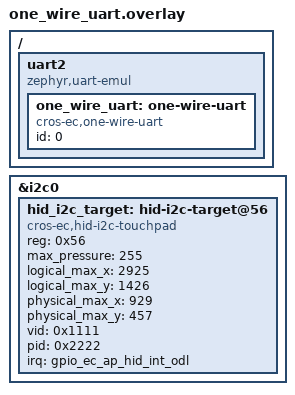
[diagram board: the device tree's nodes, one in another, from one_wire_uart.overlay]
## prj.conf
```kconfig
# Copyright 2023 The ChromiumOS Authors
# Use of this source code is governed by a BSD-style license that can be
# found in the LICENSE file.

CONFIG_ZTEST=y
CONFIG_ZTEST_NEW_API=y
CONFIG_PLATFORM_EC=y
CONFIG_CROS_EC=y

CONFIG_PLATFORM_EC_ONE_WIRE_UART_TABLET=y
CONFIG_PLATFORM_EC_ONE_WIRE_UART_KEYBOARD=y
```

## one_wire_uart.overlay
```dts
/* Copyright 2023 The ChromiumOS Authors
 * Use of this source code is governed by a BSD-style license that can be
 * found in the LICENSE file.
 */

#include <board-overlays/native_posix.dts>

/ {
	uart2 {
		compatible = "zephyr,uart-emul";
		status = "okay";

		one_wire_uart: one-wire-uart {
			compatible = "cros-ec,one-wire-uart";
			status = "okay";
			id = <0>;
		};
	};
};

&i2c0 {
	hid_i2c_target: hid-i2c-target@56 {
		compatible = "cros-ec,hid-i2c-touchpad";

		reg = <0x56>;
		max_pressure = <255>;
		logical_max_x = <2925>;
		logical_max_y = <1426>;
		physical_max_x = <929>;
		physical_max_y = <457>;

		vid = <0x1111>;
		pid = <0x2222>;

		irq = <&gpio_ec_ap_hid_int_odl>;
	};
};
```

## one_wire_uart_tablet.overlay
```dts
/* Copyright 2023 The ChromiumOS Authors
 * Use of this source code is governed by a BSD-style license that can be
 * found in the LICENSE file.
 */

&i2c0 {
	hid_i2c_target: hid-i2c-target@57 {
		compatible = "cros-ec,hid-i2c-touchpad";

		reg = <0x56>;
		max-pressure = <255>;
		logical-max-x = <2925>;
		logical-max-y = <1426>;
		physical-max-x = <929>;
		physical-max-y = <457>;

		vid = <0x1111>;
		pid = <0x2222>;

		irq-gpios = <&gpio1 16 GPIO_ACTIVE_LOW>;
	};
};
```

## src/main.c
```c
/* Copyright 2023 The ChromiumOS Authors
 * Use of this source code is governed by a BSD-style license that can be
 * found in the LICENSE file.
 */
#include "drivers/one_wire_uart.h"
#include "drivers/one_wire_uart_internal.h"
#include "test/drivers/test_state.h"
#include "test/drivers/utils.h"
#include "timer.h"

#include <stdint.h>
#include <stdlib.h>

#include <zephyr/device.h>
#include <zephyr/devicetree.h>
#include <zephyr/fff.h>
#include <zephyr/ztest_assert.h>
#include <zephyr/ztest_test.h>

const static struct device *dev = DEVICE_DT_GET(DT_NODELABEL(one_wire_uart));

FAKE_VOID_FUNC(on_message_received, uint8_t, const uint8_t *, int);

ZTEST(one_wire_uart_driver, test_checksum)
{
	struct one_wire_uart_message msg;

	memset(&msg, 0, sizeof(msg));
	msg.header.payload_len = 5;
	msg.payload[0] = 0xA1;
	msg.payload[1] = 0xA2;
	msg.payload[2] = 0xA3;
	msg.payload[3] = 0xA4;
	msg.payload[4] = 0xA5;

	/* 16bit words in the msg are [0x0500, 0x0000, 0xA100, 0xA3A2, 0xA5A4]
	 * sum = 0x1EF46 => carry back => 0xEF47
	 */
	zassert_equal(checksum(&msg), 0xEF47);
}

ZTEST(one_wire_uart_driver, test_send)
{
	struct one_wire_uart_data *data = dev->data;
	struct k_msgq *tx_queue = data->tx_queue;

	struct one_wire_uart_message msg;

	one_wire_uart_send(dev, 5, (uint8_t[]){ 6, 7, 8 }, 3);

	k_msgq_get(tx_queue, &msg, K_NO_WAIT);

	zassert_equal(msg.payload[0], 5);
	zassert_equal(msg.payload[1], 6);
	zassert_equal(msg.payload[2], 7);
	zassert_equal(msg.payload[3], 8);
}

ZTEST(one_wire_uart_driver, test_rx)
{
	struct one_wire_uart_data *data = dev->data;
	struct one_wire_uart_message msg;
	uint8_t junk[10] = {};

	memset(&msg, 0, sizeof(msg));

	/* push some junk data first */
	ring_buf_put(data->rx_ring_buf, junk, sizeof(junk));

	/* push 3 messages
	 * expect that on_message_received callback only triggered on the last
	 * message which sender == 1.
	 */
	msg.header.magic = 0xEC;
	msg.header.payload_len = 2;
	msg.payload[0] = 56;
	msg.header.sender = 0;
	msg.header.msg_id = 11;
	msg.header.checksum = 0;
	msg.header.checksum = checksum(&msg);
	ring_buf_put(data->rx_ring_buf, (uint8_t *)&msg,
		     sizeof(msg.header) + 2);

	msg.header.magic = 0xEC;
	msg.header.payload_len = 1;
	msg.payload[0] = 56;
	msg.header.sender = 0;
	msg.header.msg_id = 12;
	msg.header.checksum = 0;
	msg.header.checksum = checksum(&msg);
	ring_buf_put(data->rx_ring_buf, (uint8_t *)&msg,
		     sizeof(msg.header) + 1);

	msg.header.magic = 0xEC;
	msg.header.payload_len = 1;
	msg.payload[0] = 56;
	msg.header.sender = 1;
	msg.header.msg_id = 22;
	msg.header.checksum = 0;
	msg.header.checksum = checksum(&msg);
	ring_buf_put(data->rx_ring_buf, (uint8_t *)&msg,
		     sizeof(msg.header) + 1);

	/* push more junk */
	ring_buf_put(data->rx_ring_buf, junk, sizeof(junk));

	process_rx_fifo(dev);
	process_packet();

	zassert_equal(ring_buf_size_get(data->rx_ring_buf), 0);
	zassert_equal(on_message_received_fake.call_count, 1, "call count %d",
		      on_message_received_fake.call_count);
}

ZTEST(one_wire_uart_driver, test_rx_partial)
{
	struct one_wire_uart_data *data = dev->data;
	struct one_wire_uart_message msg;

	memset(&msg, 0, sizeof(msg));
	msg.header.magic = 0xEC;
	msg.header.payload_len = 10;
	msg.payload[0] = 56;
	msg.header.sender = 1;
	msg.header.msg_id = 11;
	msg.header.checksum = 0;
	msg.header.checksum = checksum(&msg);
	/* put 1 byte payload into ring_buf, discard other 9 bytes */
	ring_buf_put(data->rx_ring_buf, (uint8_t *)&msg,
		     sizeof(msg.header) + 1);

	one_wire_uart_set_callback(dev, on_message_received);

	process_rx_fifo(dev);
	process_packet();

	zassert_equal(on_message_received_fake.call_count, 0);
	zassert_not_equal(ring_buf_size_get(data->rx_ring_buf), 0);
}

ZTEST(one_wire_uart_driver, test_rx_bad_checksum)
{
	struct one_wire_uart_data *data = dev->data;
	struct one_wire_uart_message msg;

	memset(&msg, 0, sizeof(msg));
	msg.header.magic = 0xEC;
	msg.header.payload_len = 0;
	msg.header.sender = 1;
	msg.header.msg_id = 11;
	msg.header.checksum = 0;
	ring_buf_put(data->rx_ring_buf, (uint8_t *)&msg, sizeof(msg.header));

	one_wire_uart_set_callback(dev, on_message_received);

	process_rx_fifo(dev);
	process_packet();

	zassert_equal(on_message_received_fake.call_count, 0);
}

ZTEST(one_wire_uart_driver, test_rx_ack)
{
	struct one_wire_uart_data *data = dev->data;
	struct one_wire_uart_message msg;

	memset(&msg, 0, sizeof(msg));
	msg.header.magic = 0xEC;
	msg.header.payload_len = 0;
	msg.header.sender = 1;
	msg.header.ack = 1;
	msg.header.msg_id = 11;
	msg.header.checksum = 0;
	msg.header.checksum = checksum(&msg);
	ring_buf_put(data->rx_ring_buf, (uint8_t *)&msg, sizeof(msg.header));

	process_rx_fifo(dev);

	zassert_equal(ring_buf_size_get(data->rx_ring_buf), 0);
	zassert_equal(data->ack, 11, "ack %d", data->ack);
}

ZTEST(one_wire_uart_driver, test_tx)
{
	struct one_wire_uart_data *data = dev->data;
	struct one_wire_uart_message msg;
	static timestamp_t fake_time;

	get_time_mock = &fake_time;

	/* don't care the actual content, random bytes is fine here */
	msg.header.msg_id = 0;
	msg.header.payload_len = 0;
	k_msgq_put(data->tx_queue, &msg, K_NO_WAIT);

	fake_time.val = 0;
	process_tx_irq(dev);
	/* verify that we enqueued the message to ring_buf */
	zassert_equal(ring_buf_size_get(data->tx_ring_buf), sizeof(msg.header));

	ring_buf_reset(data->tx_ring_buf);
	fake_time.val = MSEC;
	process_tx_irq(dev);
	/* resend timer not expired, shouldn't enqueue any data here */
	zassert_equal(ring_buf_size_get(data->tx_ring_buf), 0);

	ring_buf_reset(data->tx_ring_buf);
	fake_time.val = 3 * MSEC;
	process_tx_irq(dev);
	/* resend timer expired, resend the same message */
	zassert_equal(ring_buf_size_get(data->tx_ring_buf), sizeof(msg.header));

	ring_buf_get(data->tx_ring_buf, NULL, 1);
	fake_time.val = 6 * MSEC;
	process_tx_irq(dev);
	/* resend timer expired, but tx_ring_buf not fully consumed,
	 * don't queue the next pending message.
	 */
	zassert_equal(ring_buf_size_get(data->tx_ring_buf),
		      sizeof(msg.header) - 1);

	ring_buf_reset(data->tx_ring_buf);
	data->ack = 0;
	fake_time.val = 10 * MSEC;
	process_tx_irq(dev);
	/* ACK'ed, nothing queued this time */
	zassert_equal(ring_buf_size_get(data->tx_ring_buf), 0);

	get_time_mock = NULL;
}

ZTEST(one_wire_uart_driver, test_bad_packet_length)
{
	struct one_wire_uart_data *data = dev->data;
	struct one_wire_uart_message msg;

	memset(&msg, 0, sizeof(msg));
	msg.header.magic = 0xEC;
	msg.header.payload_len = 255;
	msg.header.sender = 1;
	msg.header.ack = 1;
	msg.header.msg_id = 11;
	msg.header.checksum = 0;
	ring_buf_put(data->rx_ring_buf, (uint8_t *)&msg, sizeof(msg.header));

	process_rx_fifo(dev);

	/* expect that process_rx_fifo will flush the fifo without waiting for
	 * payload_len(=255) bytes of data arrive
	 */
	zassert_equal(ring_buf_size_get(data->rx_ring_buf), 0);
}

ZTEST(one_wire_uart_driver, test_reset)
{
	struct one_wire_uart_data *data = dev->data;
	struct one_wire_uart_message msg;

	memset(&msg, 0, sizeof(msg));
	msg.header.magic = 0xEC;
	msg.header.sender = 1;
	msg.header.msg_id = 11;
	msg.header.reset = 1;
	msg.header.checksum = 0;
	msg.header.checksum = checksum(&msg);
	ring_buf_put(data->rx_ring_buf, (uint8_t *)&msg, sizeof(msg.header));

	ring_buf_put(data->tx_ring_buf, "123", 3);

	process_rx_fifo(dev);

	/* expect that
	 * 1. the junk data in tx_ring_buf is cleared
	 * 2. an ack message is push into tx_ring_buf
	 */
	zassert_equal(ring_buf_size_get(data->tx_ring_buf), sizeof(msg.header));
	ring_buf_get(data->tx_ring_buf, (uint8_t *)&msg, sizeof(msg.header));
	zassert_equal(msg.header.ack, 1);
	zassert_equal(msg.header.msg_id, 11);
	zassert_equal(msg.header.reset, 0);
}

ZTEST(one_wire_uart_driver, test_max_retry_count)
{
	struct one_wire_uart_data *data = dev->data;
	struct one_wire_uart_message msg;
	const int MAX_RETRY = 50;
	const k_timeout_t RESEND_DELAY = K_MSEC(3);

	memset(&msg, 0, sizeof(msg));
	msg.header.magic = 0xEC;
	msg.header.sender = 1;
	msg.header.msg_id = 11;
	msg.header.checksum = 0;
	msg.header.checksum = checksum(&msg);
	k_msgq_put(data->tx_queue, &msg, K_NO_WAIT);

	for (int i = 0; i < MAX_RETRY; i++) {
		ring_buf_reset(data->tx_ring_buf);
		k_sleep(RESEND_DELAY);
		process_tx_irq(dev);
		zassert_equal(data->retry_count, i + 1);
	}

	/* expect that RESET message is queued */
	ring_buf_reset(data->tx_ring_buf);
	k_sleep(RESEND_DELAY);
	process_tx_irq(dev);
	/* wait for deferred task */
	k_sleep(K_SECONDS(1));
	zassert_ok(k_msgq_peek(data->tx_queue, &msg));
	zassert_equal(msg.header.reset, 1);

	/* send RETRY 10 times */
	for (int i = 0; i < MAX_RETRY; i++) {
		ring_buf_reset(data->tx_ring_buf);
		k_sleep(RESEND_DELAY);
		process_tx_irq(dev);
		zassert_equal(data->retry_count, i + 1);
	}

	/* expect that nothing queued when failed to send RETRY */
	ring_buf_reset(data->tx_ring_buf);
	k_sleep(RESEND_DELAY);
	process_tx_irq(dev);
	zassert_equal(k_msgq_num_used_get(data->tx_queue), 0);
}

ZTEST(one_wire_uart_driver, test_disable)
{
	struct one_wire_uart_data *data = dev->data;
	struct k_msgq *tx_queue = data->tx_queue;

	one_wire_uart_disable(dev);

	zassert_equal(one_wire_uart_send(dev, 1, NULL, 0), -EINVAL);
	zassert_equal(k_msgq_num_used_get(tx_queue), 0);
}

struct one_wire_uart_fixture {
	one_wire_uart_msg_received_cb_t orig_cb;
};

static void *one_wire_uart_setup(void)
{
	struct one_wire_uart_data *data = dev->data;

	struct one_wire_uart_fixture *fixture =
		malloc(sizeof(struct one_wire_uart_fixture));

	fixture->orig_cb = data->msg_received_cb;
	one_wire_uart_set_callback(dev, on_message_received);

	return fixture;
}

static void one_wire_uart_driver_before(void *f)
{
	one_wire_uart_enable(dev);
	one_wire_uart_reset(dev);

	RESET_FAKE(on_message_received);
}

static void one_wire_uart_teardown(void *f)
{
	struct one_wire_uart_fixture *fixture = f;

	one_wire_uart_set_callback(dev, fixture->orig_cb);
}

ZTEST_SUITE(one_wire_uart_driver, drivers_predicate_post_main,
	    one_wire_uart_setup, one_wire_uart_driver_before, NULL,
	    one_wire_uart_teardown);
```

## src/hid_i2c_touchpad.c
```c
/* Copyright 2023 The ChromiumOS Authors
 * Use of this source code is governed by a BSD-style license that can be
 * found in the LICENSE file.
 */
#include "ap_power/ap_power.h"
#include "ap_power/ap_power_events.h"
#include "drivers/one_wire_uart.h"
#include "drivers/one_wire_uart_internal.h"
#include "gpio_signal.h"
#include "keyboard_config.h"
#include "test/drivers/test_state.h"
#include "test/drivers/utils.h"
#include "usb_hid_touchpad.h"

#include <stdint.h>

#include <zephyr/device.h>
#include <zephyr/devicetree.h>
#include <zephyr/drivers/i2c.h>
#include <zephyr/sys/byteorder.h>
#include <zephyr/ztest_assert.h>
#include <zephyr/ztest_test_new.h>

const static struct device *dev = DEVICE_DT_GET(DT_NODELABEL(hid_i2c_target));

ZTEST(hid_i2c_touchpad, test_reset_flow)
{
	const struct gpio_dt_spec *hid_irq =
		GPIO_DT_FROM_NODELABEL(gpio_ec_ap_hid_int_odl);
	struct i2c_target_data *data = dev->data;
	struct i2c_target_config *target_cfg = &data->config;
	const struct i2c_target_callbacks *callbacks = target_cfg->callbacks;
	uint8_t cmd[] = { 0x5, 0x00, 0x00, 0x01 }; /* reset command */
	uint8_t *read_ptr;
	uint32_t read_len;

	callbacks->buf_write_received(target_cfg, cmd, sizeof(cmd));
	callbacks->stop(target_cfg);

	/* 7.2.1.2 At the end of the reset, the DEVICE must also write a 2 Byte
	 * value to the Input Register with the sentinel value of 0x0000
	 * (2 Bytes containing 0) and must assert the Interrupt to indicate that
	 * it has been initialized
	 */
	zassert_equal(gpio_emul_output_get(hid_irq->port, hid_irq->pin), 0);
	zassert_equal(data->in_reset, true);

	callbacks->buf_read_requested(target_cfg, &read_ptr, &read_len);
	callbacks->stop(target_cfg);
	zassert_equal(read_len, 2);
	zassert_equal(read_ptr[0], 0);
	zassert_equal(read_ptr[1], 0);
	zassert_equal(gpio_emul_output_get(hid_irq->port, hid_irq->pin), 1);
}

ZTEST(hid_i2c_touchpad, test_touchpad_event)
{
	const struct gpio_dt_spec *hid_irq =
		GPIO_DT_FROM_NODELABEL(gpio_ec_ap_hid_int_odl);
	struct i2c_target_data *data = dev->data;
	struct i2c_target_config *target_cfg = &data->config;
	const struct i2c_target_callbacks *callbacks = target_cfg->callbacks;
	uint8_t *read_ptr;
	uint32_t read_len;
	struct usb_hid_touchpad_report expected1, expected2;

	memset(&expected1, 0x56, sizeof(struct usb_hid_touchpad_report));
	memset(&expected2, 0x78, sizeof(struct usb_hid_touchpad_report));
	hid_i2c_touchpad_add(dev, &expected1);
	hid_i2c_touchpad_add(dev, &expected2);

	zassert_equal(gpio_emul_output_get(hid_irq->port, hid_irq->pin), 0);

	/* first read should return `expected1`, and irq keep asserted because
	 * there's another event queued
	 */
	callbacks->buf_read_requested(target_cfg, &read_ptr, &read_len);
	callbacks->stop(target_cfg);
	zassert_equal(read_len, sizeof(struct usb_hid_touchpad_report) + 2);
	zassert_equal(sys_get_le16(read_ptr),
		      sizeof(struct usb_hid_touchpad_report));
	zassert_mem_equal(&expected1, read_ptr + 2,
			  sizeof(struct usb_hid_touchpad_report));
	zassert_equal(gpio_emul_output_get(hid_irq->port, hid_irq->pin), 0);

	/* second read should return `expected2`, and deassert the irq */
	callbacks->buf_read_requested(target_cfg, &read_ptr, &read_len);
	callbacks->stop(target_cfg);
	zassert_equal(read_len, sizeof(struct usb_hid_touchpad_report) + 2);
	zassert_equal(sys_get_le16(read_ptr),
		      sizeof(struct usb_hid_touchpad_report));
	zassert_mem_equal(&expected2, read_ptr + 2,
			  sizeof(struct usb_hid_touchpad_report));
	zassert_equal(gpio_emul_output_get(hid_irq->port, hid_irq->pin), 1);
}

ZTEST(hid_i2c_touchpad, test_descriptor)
{
	struct i2c_target_data *data = dev->data;
	struct i2c_target_config *target_cfg = &data->config;
	const struct i2c_target_callbacks *callbacks = target_cfg->callbacks;
	uint8_t *read_ptr;
	uint32_t read_len;

	uint16_t hid_desc_reg = 1;
	/* read HID descriptor */
	callbacks->buf_write_received(target_cfg, (uint8_t *)&hid_desc_reg,
				      sizeof(hid_desc_reg));
	callbacks->buf_read_requested(target_cfg, &read_ptr, &read_len);
	callbacks->stop(target_cfg);

	/* HID descriptor is always 30 bytes */
	zassert_equal(read_len, 30);

	uint16_t report_desc_len = sys_get_le16(read_ptr + 4);
	uint16_t report_desc_reg = sys_get_le16(read_ptr + 6);

	callbacks->buf_write_received(target_cfg, (uint8_t *)&report_desc_reg,
				      sizeof(report_desc_reg));
	callbacks->buf_read_requested(target_cfg, &read_ptr, &read_len);
	callbacks->stop(target_cfg);
	/* verify that the length of return report equals to the
	 * `wReportDescRegister` field in the HID descriptor
	 */
	zassert_equal(read_len, report_desc_len);
}

ZTEST(hid_i2c_touchpad, test_bad_input)
{
	struct i2c_target_data *data = dev->data;
	struct i2c_target_config *target_cfg = &data->config;
	const struct i2c_target_callbacks *callbacks = target_cfg->callbacks;
	uint8_t *read_ptr;
	uint32_t read_len;
	uint8_t bad_input_1[] = { 0x5, 0x00 }; /* cmd register without data */
	uint8_t bad_input_2[] = { 0x99, 0x00 }; /* undefined register */

	callbacks->buf_write_received(target_cfg, bad_input_1,
				      sizeof(bad_input_1));
	callbacks->buf_read_requested(target_cfg, &read_ptr, &read_len);
	callbacks->stop(target_cfg);
	zassert_equal(0, read_len);

	callbacks->buf_write_received(target_cfg, bad_input_2,
				      sizeof(bad_input_1));
	callbacks->buf_read_requested(target_cfg, &read_ptr, &read_len);
	callbacks->stop(target_cfg);
	zassert_equal(0, read_len);
}

static void hid_i2c_touchpad_before(void *fixture)
{
	const struct gpio_dt_spec *hid_irq =
		GPIO_DT_FROM_NODELABEL(gpio_ec_ap_hid_int_odl);

	gpio_pin_set_dt(hid_irq, 1);
}

ZTEST_SUITE(hid_i2c_touchpad, drivers_predicate_post_main, NULL,
	    hid_i2c_touchpad_before, NULL, NULL);
```

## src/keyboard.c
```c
/* Copyright 2023 The ChromiumOS Authors
 * Use of this source code is governed by a BSD-style license that can be
 * found in the LICENSE file.
 */
#include "drivers/one_wire_uart.h"
#include "drivers/one_wire_uart_internal.h"
#include "drivers/usb_stream.h"
#include "keyboard_config.h"
#include "keyboard_scan.h"
#include "queue.h"
#include "test/drivers/test_state.h"
#include "test/drivers/utils.h"
#include "touchpad.h"
#include "usb_hid_touchpad.h"

#include <stdint.h>

#include <zephyr/device.h>
#include <zephyr/fff.h>
#include <zephyr/ztest_assert.h>
#include <zephyr/ztest_test.h>

void keyboard_state_changed(int row, int col, int is_pressed);

const static struct device *dev = DEVICE_DT_GET(DT_NODELABEL(one_wire_uart));

static const struct queue update_to_usb = QUEUE_NULL(64, uint8_t);
static const struct queue usb_to_update = QUEUE_NULL(64, uint8_t);
USB_STREAM_CONFIG_FULL(usb_update, 0, 0, 0, 0, 0, 0, 0, 0, usb_to_update,
		       update_to_usb, 0, 0);

FAKE_VALUE_FUNC(int, mkbp_keyboard_add, const uint8_t *);

ZTEST(one_wire_uart_keyboard, test_keyboard_event)
{
	struct one_wire_uart_data *data = dev->data;
	struct one_wire_uart_message msg;
	uint8_t expected_key_state[KEYBOARD_COLS_MAX] = {};

	test_keyboard_scan_debounce_reset();

	keyboard_state_changed(0, 0, 1);
	zassert_equal(k_msgq_num_used_get(data->tx_queue), 1);
	zassert_ok(k_msgq_get(data->tx_queue, &msg, K_NO_WAIT));
	zassert_equal(msg.header.payload_len, KEYBOARD_COLS_MAX + 1);
	zassert_equal(msg.payload[0], ROACH_CMD_KEYBOARD_MATRIX);
	expected_key_state[0] = 1;
	zassert_mem_equal(msg.payload + 1, expected_key_state,
			  KEYBOARD_COLS_MAX);

	keyboard_state_changed(0, 0, 0);
	zassert_ok(k_msgq_get(data->tx_queue, &msg, K_NO_WAIT));
	zassert_equal(msg.header.payload_len, KEYBOARD_COLS_MAX + 1);
	zassert_equal(msg.payload[0], ROACH_CMD_KEYBOARD_MATRIX);
	expected_key_state[0] = 0;
	zassert_mem_equal(msg.payload + 1, expected_key_state,
			  KEYBOARD_COLS_MAX);
}

ZTEST(one_wire_uart_keyboard, test_touchpad_event)
{
	struct one_wire_uart_data *data = dev->data;
	struct one_wire_uart_message msg;
	struct usb_hid_touchpad_report report;

	set_touchpad_report(&report);
	zassert_ok(k_msgq_get(data->tx_queue, &msg, K_NO_WAIT));
	zassert_equal(msg.header.payload_len, sizeof(report) + 1);
	zassert_equal(msg.payload[0], ROACH_CMD_TOUCHPAD_REPORT);
	zassert_mem_equal(msg.payload + 1, &report, sizeof(report));
}

ZTEST(one_wire_uart_keyboard, test_ap_to_updater)
{
	struct one_wire_uart_data *data = dev->data;
	struct one_wire_uart_message msg;
	const uint8_t expected[4] = { 1, 2, 3, 4 };
	uint8_t actual[4];

	memset(&msg, 0, sizeof(msg));
	msg.header.magic = 0xEC;
	msg.header.payload_len = sizeof(expected) + 1;
	msg.header.sender = 1;
	msg.header.msg_id = 1;
	msg.payload[0] = ROACH_CMD_UPDATER_COMMAND;
	memcpy(msg.payload + 1, expected, sizeof(expected));
	msg.header.checksum = checksum(&msg);

	ring_buf_put(data->rx_ring_buf, (uint8_t *)&msg,
		     sizeof(msg.header) + msg.header.payload_len);

	process_rx_fifo(dev);
	process_packet();

	zassert_equal(queue_count(&usb_to_update), sizeof(expected));
	queue_remove_units(&usb_to_update, actual, sizeof(actual));
	zassert_mem_equal(actual, expected, sizeof(expected));
}

ZTEST(one_wire_uart_keyboard, test_updater_to_ap)
{
	struct one_wire_uart_data *data = dev->data;
	const uint8_t expected[4] = { 1, 2, 3, 4 };
	struct one_wire_uart_message msg;

	queue_add_units(&update_to_usb, expected, sizeof(expected));
	usb_update.consumer.ops->written(&usb_update.consumer,
					 sizeof(expected));

	zassert_true(queue_is_empty(&update_to_usb));
	zassert_equal(k_msgq_num_used_get(data->tx_queue), 1);
	k_msgq_get(data->tx_queue, &msg, K_NO_WAIT);
	zassert_equal(msg.payload[0], ROACH_CMD_UPDATER_COMMAND);
	zassert_mem_equal(msg.payload + 1, expected, sizeof(expected));
}

static void keyboard_before(void *fixture)
{
	one_wire_uart_reset(dev);

	RESET_FAKE(mkbp_keyboard_add);
}

ZTEST_SUITE(one_wire_uart_keyboard, drivers_predicate_post_main, NULL,
	    keyboard_before, NULL, NULL);
```

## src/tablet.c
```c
/* Copyright 2023 The ChromiumOS Authors
 * Use of this source code is governed by a BSD-style license that can be
 * found in the LICENSE file.
 */
#include "ap_power/ap_power.h"
#include "ap_power/ap_power_events.h"
#include "drivers/one_wire_uart.h"
#include "drivers/one_wire_uart_internal.h"
#include "gpio_signal.h"
#include "keyboard_config.h"
#include "test/drivers/test_state.h"
#include "test/drivers/utils.h"
#include "usb_hid_touchpad.h"

#include <stdint.h>

#include <zephyr/device.h>
#include <zephyr/devicetree.h>
#include <zephyr/fff.h>
#include <zephyr/ztest_assert.h>
#include <zephyr/ztest_test.h>

const static struct device *dev = DEVICE_DT_GET(DT_NODELABEL(one_wire_uart));
const static struct device *touchpad =
	DEVICE_DT_GET(DT_NODELABEL(hid_i2c_target));

FAKE_VALUE_FUNC(int, mkbp_keyboard_add, const uint8_t *);
FAKE_VALUE_FUNC(int, base_get_state);

ZTEST(one_wire_uart_tablet, test_keyboard_event)
{
	struct one_wire_uart_data *data = dev->data;
	struct one_wire_uart_message msg;
	const struct gpio_dt_spec *hid_irq =
		GPIO_DT_FROM_NODELABEL(gpio_ec_ap_hid_int_odl);

	memset(&msg, 0, sizeof(msg));
	msg.header.magic = 0xEC;
	msg.header.payload_len = KEYBOARD_COLS_MAX + 1;
	msg.payload[0] = ROACH_CMD_KEYBOARD_MATRIX;
	msg.header.sender = 1;
	msg.header.msg_id = 1;
	msg.header.checksum = checksum(&msg);
	ring_buf_put(data->rx_ring_buf, (uint8_t *)&msg,
		     sizeof(msg.header) + msg.header.payload_len);

	process_rx_fifo(dev);
	process_packet();

	zassert_equal(mkbp_keyboard_add_fake.call_count, 1);
	zassert_equal(gpio_emul_output_get(hid_irq->port, hid_irq->pin), 1);
}

ZTEST(one_wire_uart_tablet, test_touchpad_event)
{
	struct one_wire_uart_data *data = dev->data;
	struct one_wire_uart_message msg;
	const struct gpio_dt_spec *hid_irq =
		GPIO_DT_FROM_NODELABEL(gpio_ec_ap_hid_int_odl);

	memset(&msg, 0, sizeof(msg));
	msg.header.magic = 0xEC;
	msg.header.payload_len = sizeof(struct usb_hid_touchpad_report) + 1;
	msg.payload[0] = ROACH_CMD_TOUCHPAD_REPORT;
	msg.header.sender = 1;
	msg.header.msg_id = 1;
	msg.header.checksum = checksum(&msg);
	ring_buf_put(data->rx_ring_buf, (uint8_t *)&msg,
		     sizeof(msg.header) + msg.header.payload_len);

	process_rx_fifo(dev);
	process_packet();

	zassert_equal(mkbp_keyboard_add_fake.call_count, 0);
	zassert_equal(gpio_emul_output_get(hid_irq->port, hid_irq->pin), 0);
}

ZTEST(one_wire_uart_tablet, test_ap_power_state)
{
	struct one_wire_uart_data *data = dev->data;
	struct one_wire_uart_message msg;

	ap_power_ev_send_callbacks(AP_POWER_SHUTDOWN);
	zassert_equal(k_msgq_num_used_get(data->tx_queue), 1);
	zassert_ok(k_msgq_get(data->tx_queue, &msg, K_NO_WAIT));
	zassert_equal(msg.payload[0], ROACH_CMD_SUSPEND);

	ap_power_ev_send_callbacks(AP_POWER_STARTUP);
	zassert_equal(k_msgq_num_used_get(data->tx_queue), 1);
	zassert_ok(k_msgq_get(data->tx_queue, &msg, K_NO_WAIT));
	zassert_equal(msg.payload[0], ROACH_CMD_RESUME);
}

ZTEST(one_wire_uart_tablet, test_updater_event)
{
	struct one_wire_uart_data *data = dev->data;
	struct i2c_target_data *tp_data = touchpad->data;
	struct one_wire_uart_message msg;
	const uint8_t expected[4] = { 1, 2, 3, 4 };
	uint8_t actual[4];

	memset(&msg, 0, sizeof(msg));
	msg.header.magic = 0xEC;
	msg.header.payload_len = sizeof(expected) + 1;
	msg.header.sender = 1;
	msg.header.msg_id = 1;
	msg.payload[0] = ROACH_CMD_UPDATER_COMMAND;
	memcpy(msg.payload + 1, expected, sizeof(expected));
	msg.header.checksum = checksum(&msg);

	ring_buf_put(data->rx_ring_buf, (uint8_t *)&msg,
		     sizeof(msg.header) + msg.header.payload_len);

	process_rx_fifo(dev);
	process_packet();

	zassert_equal(ring_buf_size_get(tp_data->usb_update_queue),
		      sizeof(expected));
	ring_buf_get(tp_data->usb_update_queue, actual, sizeof(actual));
	zassert_mem_equal(actual, expected, sizeof(expected));
}

static void tablet_before(void *fixture)
{
	const struct gpio_dt_spec *hid_irq =
		GPIO_DT_FROM_NODELABEL(gpio_ec_ap_hid_int_odl);

	one_wire_uart_enable(dev);
	one_wire_uart_reset(dev);

	RESET_FAKE(mkbp_keyboard_add);
	gpio_pin_set_dt(hid_irq, 0);
	base_get_state_fake.return_val = 1;
}

ZTEST_SUITE(one_wire_uart_tablet, drivers_predicate_post_main, NULL,
	    tablet_before, NULL, NULL);
```
